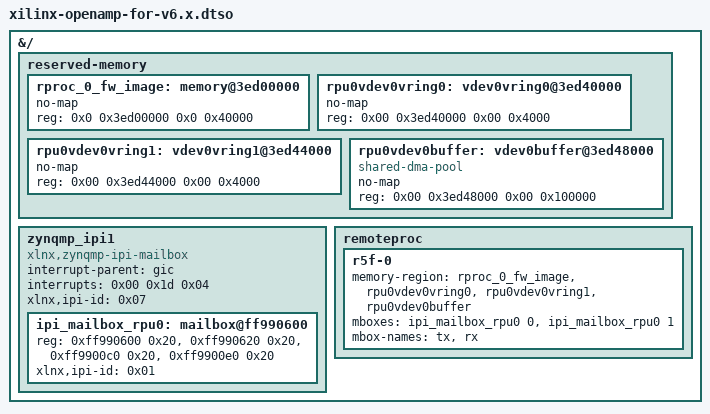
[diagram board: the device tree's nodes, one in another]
/* Applies to all zynqmp boards to configure the IPC & memory for OpenAMP
**
** This configuration is compatible with old bare-metal apps built with
** petalinux v2023 and before.
**
** It uses different IPC interrupt channels
** It only supports lockstep mode
**
** Bare-metal apps that do not use rpmsg (or any other IPI) can use the normal
** dtbs and thus can support lockstep and split mode.
*/

/dts-v1/;
/plugin/;

&{/} {
	#address-cells = <2>;
	#size-cells = <2>;

	reserved-memory {
		#address-cells = <0x02>;
		#size-cells = <0x02>;
		ranges;

		rproc_0_fw_image: memory@3ed00000 {
			no-map;
			reg = <0x0 0x3ed00000 0x0 0x40000>;
		};

		rpu0vdev0vring0: vdev0vring0@3ed40000 {
			no-map;
			reg = <0x00 0x3ed40000 0x00 0x4000>;
		};

		rpu0vdev0vring1: vdev0vring1@3ed44000 {
			no-map;
			reg = <0x00 0x3ed44000 0x00 0x4000>;
		};

		rpu0vdev0buffer: vdev0buffer@3ed48000 {
			no-map;
			compatible = "shared-dma-pool";
			reg = <0x00 0x3ed48000 0x00 0x100000>;
		};

	};

	zynqmp_ipi1 {
		compatible = "xlnx,zynqmp-ipi-mailbox";
		interrupt-parent = <&gic>;
		interrupts = <0x00 0x1d 0x04>;
		xlnx,ipi-id = <0x07>;        /* bare-metal apps send on channel 7 */
		#address-cells = <0x01>;
		#size-cells = <0x01>;
		ranges;

		ipi_mailbox_rpu0: mailbox@ff990600 {
			reg = <0xff990600 0x20>,
			      <0xff990620 0x20>,
			      <0xff9900c0 0x20>,
			      <0xff9900e0 0x20>;
			reg-names = "local_request_region",
			            "local_response_region",
				    "remote_request_region",
				    "remote_response_region";
			#mbox-cells = <0x01>;
			xlnx,ipi-id = <0x01>;    /* host still sends to RPU0 on ch 1 */
		};
	};

	remoteproc: remoteproc {
		r5f-0 {
			memory-region = <&rproc_0_fw_image>, <&rpu0vdev0vring0>,
					<&rpu0vdev0vring1>, <&rpu0vdev0buffer>;
			mboxes = <&ipi_mailbox_rpu0 0>, <&ipi_mailbox_rpu0 1>;
			mbox-names = "tx", "rx";
		};
	};
};
